# AE1C1F4051920PH0_CM55_HE_View register map
Vendor: Alif Semiconductor; Series: E1; File version: 1.0
CPU: CM55 r1p0, selectable endian, MPU, FPU, double-precision FPU, DSP, VTOR, 8 interrupt priority bits, 1 SAU regions
Registers are 32-bit, read-write, reset 0x0 unless marked. A register's access mark holds for its fields unless they carry their own. Offsets are from the block's base; [hi:lo] are bit positions.

## REFCLK_CNTControl
Base 0x1A200000
Same registers: S32K_CNTControl 0x1A400000
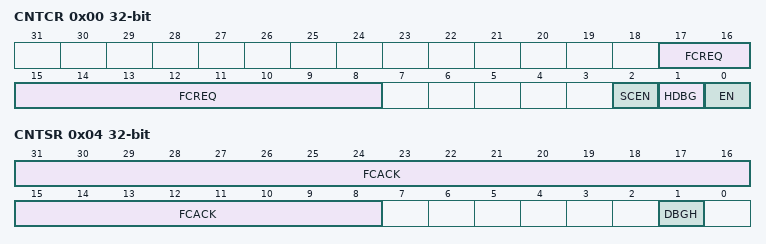
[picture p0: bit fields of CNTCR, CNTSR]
0x00 CNTCR (reset mask 0xFFFFFFF9) — Counter Control Register
  [17:8] FCREQ — Frequency change request. Specifies the index of the CNTFIDn register that holds the counter new frequency. Changing the value of this field requests a change to the counter update frequency. Any non-required most-significant bits are read-only and reserved.
  [2] SCEN — Scale Enable. This bit can only be changed when the counter is disabled (when CNTCR[EN] = 0x0). If the value of CNTCR[SCEN] changes when CNTCR[EN] = 0x1 then the counter value becomes unknown and remains unknown on future ticks of the clock.
    0=Scaling disabled. The counter value is incremented by 0x1 for each counter tick.; 1=Scaling enabled. The counter value is incremented by CNTSCR[SCALEVAL] for each counter tick.
  [1] HDBG — Halt-on-debug. Controls whether a halt-on-debug request halts the system counter.
    0=The counter ignores the halt-on-debug request; 1=When the halt-on-debug request is activated the counter halts
  [0] EN — Counter enable.
    0=System counter disabled; 1=System counter enabled
0x04 CNTSR ro (reset mask 0xFFFFFFFD) — Counter Status Register
  [31:8] FCACK — Frequency change acknowledge. Specifies the index of the CNTFIDn register that holds the counter new frequency.
  [1] DBGH — Indicates whether the counter is halted because of a halt-on-debug request.
    0=Counter is not halted; 1=Counter is halted
0x08 CNTCVL reset not defined — Counter Count Value Low Register
  [31:0] COUNTVALUE_LO — Bits [31:0] of the current counter value.
0x0C CNTCVH reset not defined — Counter Count Value High Register
  [31:0] COUNTVALUE_HI — Bits [63:32] of the current counter value.

## REFCLK_CNTRead
Base 0x1A210000
Same registers: S32K_CNTRead 0x1A410000
0x00 CNTCVL ro reset not defined — Read-only Version of CNTCVL Register
  [31:0] COUNTVALUE_LO — Read-only version of CNTCVL register.
0x04 CNTCVH ro reset not defined — Read-only Version of CNTCVH Register
  [31:0] COUNTVALUE_HI — Read-only version of CNTCVH register

## CGU
Base 0x1A602000
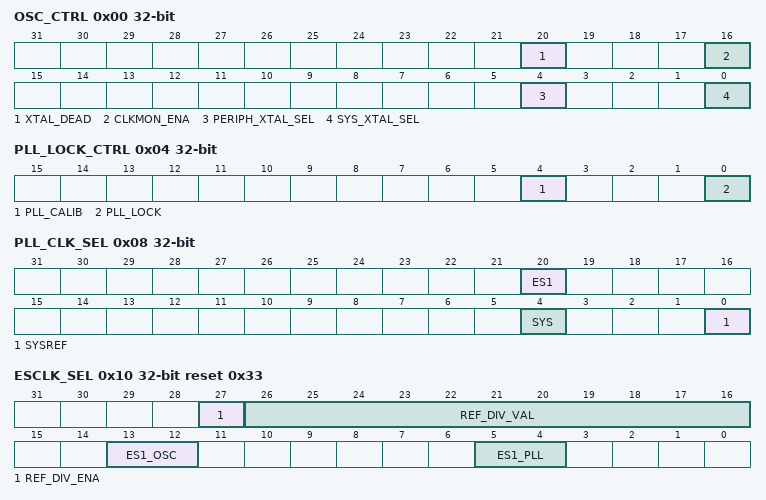
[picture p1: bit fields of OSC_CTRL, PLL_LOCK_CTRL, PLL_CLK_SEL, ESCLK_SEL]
0x00 OSC_CTRL — Oscillator Control Register
  [20] XTAL_DEAD ro — 38.4 MHz crystal-oscillator clock monitor status
    0=No crystal clock dead found; 1=Crystal clock dead detected
  [16] CLKMON_ENA — Enable 38.4 MHz crystal-oscillator clock monitor
    0=Disable clock monitor; 1=Enable clock monitor
  [4] PERIPH_XTAL_SEL — Select oscillator clock source for HFOSC_CLK
    0=Select 38.4 MHz (76.8 MHz / 2) ring-oscillator clock; 1=Select 38.4 MHz crystal-oscillator clock
  [0] SYS_XTAL_SEL — Select oscillator clock source for SYSPLL_CLK and SYST_REFCLK
    0=Select 76.8 MHz ring-oscillator clock; 1=Select 76.8 MHz (38.4 MHz x 2) crystal-oscillator clock
0x04 PLL_LOCK_CTRL — PLL Lock Control Register
  [4] PLL_CALIB ro — PLL calibration status
    0=PLL not in calibration; 1=PLL in calibration
  [0] PLL_LOCK — PLL lock control
    0=PLL not locked; 1=PLL locked
0x08 PLL_CLK_SEL — PLL Clock Select Register
  [20] ES1 — Select the source for RTSS_HE_CLK
    0=Select a value specified by the ESCLK_SEL[ES1_OSC] field; 1=Select a value specified by the ESCLK_SEL[ES1_PLL] field
  [4] SYS — Select the source for SYSPLL_CLK
    0=Select oscillator clock source; 1=Select PLL clock source
  [0] SYSREF — Select the source for SYST_REFCLK
    0=Select oscillator clock source; 1=Select PLL clock source
0x10 ESCLK_SEL reset 0x33 (reset mask 0x3FFF333) — Clock Select Register for M55-HE
  [27] REF_DIV_ENA — SYST_REFCLK divider enable
    0=Divider disabled. SYST_REFCLK is active and not divided.; 1=Divider enabled. SYST_REFCLK is active and divided by value specified in the ESCLK_SEL[REF_DIV_VAL] field.
  [26:16] REF_DIV_VAL — SYST_REFCLK divider values All other values: Reserved.
    0=Clock divided by 1; 2=Clock divided by 2; 4=Clock divided by 4; 8=Clock divided by 8; 16=Clock divided by 16; 32=Clock divided by 32; 64=Clock divided by 64; 128=Clock divided by 128; 0x100=Clock divided by 256; 0x200=Clock divided by 512; 0x400=Clock divided by 1024
  [13:12] ES1_OSC — Select oscillator clock frequency for RTSS_HE_CLK
    0=Select 76.8 MHz ring-oscillator clock; 1=Select 38.4 MHz ring-oscillator clock; 2=Select 76.8 MHz crystal-oscillator clock; 3=Select 38.4 MHz crystal-oscillator clock
  [5:4] ES1_PLL — Select PLL clock frequency for RTSS_HE_CLK
    0=Select 60 MHz PLL clock; 1=Select 80 MHz PLL clock; 2=Select 120 MHz PLL clock; 3=Select 160 MHz PLL clock
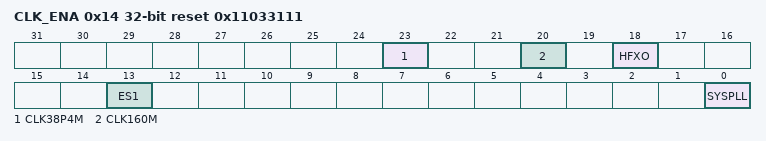
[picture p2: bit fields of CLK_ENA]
0x14 CLK_ENA reset 0x11033111 — Clock Enable Register
  [all] fields
    0=Disable clock; 1=Enable clock
  [23] CLK38P4M — Enable HFOSC_CLK
  [20] CLK160M — Enable PERIPH_CLK
  [18] HFXO — Enable clock to the HFXO_OUT pin
  [13] ES1 — Enable RTSS_HE_CLK
  [0] SYSPLL — Enable SYSPLL_CLK
0x20 CGU_IRQ ro — CGU Interrupt Status Register
  [0] XTAL_DEAD read-clears — 38.4 MHz crystal-oscillator dead. Active high, read to clear. Note: The XTAL_DEAD interrupt is mapped to the Secure Enclave.
